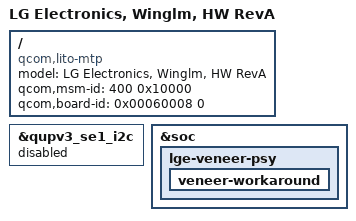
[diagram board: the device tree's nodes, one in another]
/dts-v1/;
/plugin/;

#include <dt-bindings/interrupt-controller/arm-gic.h>
#include "lito-winglm_lao_com.dtsi"
#include "lito-winglm_lao_com-pm.dtsi"
#include "../lito-camera/lito-winglm-camera_rev-a.dtsi"
#include "lito-winglm_lao_com-fingerprint.dtsi"
#include "lito-winglm_lao_com-usb.dtsi"
#include "lito-winglm_lao_com-sound_rev-a.dtsi"

/ {
	model = "LG Electronics, Winglm, HW RevA";
	compatible = "qcom,lito-mtp", "qcom,lito", "qcom,mtp";
	qcom,msm-id = <400 0x10000>;
	qcom,board-id = <0x00060008 0>;
};

&qupv3_se1_i2c {
	status = "disabled";
};

&soc {
	lge-veneer-psy {
		veneer-workaround {
			/delete-property/ lge,enable-concurrency-otg-wireless;
		};
	};
};
